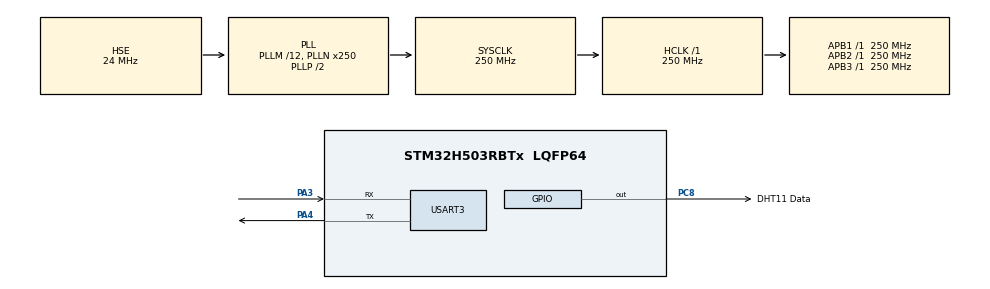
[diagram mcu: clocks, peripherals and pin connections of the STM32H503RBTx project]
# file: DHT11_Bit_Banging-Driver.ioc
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BOOTPATH.BootPathName=LEGACY
BOOTPATH.UserSelectedBootPath=LEGACY
Mcu.Family=STM32H5
Mcu.Name=STM32H503RBTx
Mcu.Package=LQFP64
NUCLEO-H503RB.LD2=false
NVIC.PriorityGroup=NVIC_PRIORITYGROUP_4
PA13(JTMS/SWDIO).GPIO_Label=T_SWDIO
PA13(JTMS/SWDIO).Signal=DEBUG_JTMS-SWDIO
PA14(JTCK/SWCLK).GPIO_Label=T_SWCLK
PA14(JTCK/SWCLK).Signal=DEBUG_JTCK-SWCLK
PA15(JTDI).GPIO_Label=T_JTDI
PA15(JTDI).Signal=DEBUG_JTDI
PA2.Signal=USART2_TX
PA3.Mode=Asynchronous
PA3.Signal=USART3_RX
PA4.Mode=Asynchronous
PA4.Signal=USART3_TX
PB14.GPIO_Label=ARD_D1_TX
PB14.Signal=USART1_TX
PB15.GPIO_Label=ARD_D0_RX
PB15.Signal=USART1_RX
PB3(JTDO/TRACESWO).GPIO_Label=T_SWO
PB3(JTDO/TRACESWO).Signal=DEBUG_JTDO-SWO
PC8.GPIO_Label=DHT11 Data
PC8.GPIO_ModeDefaultOutputPP=GPIO_MODE_OUTPUT_OD
PC8.GPIO_PuPd=GPIO_NOPULL
PC8.GPIO_Speed=GPIO_SPEED_FREQ_MEDIUM
PC8.Signal=GPIO_Output
PH0-OSC_IN(PH0).Mode=HSE-External-Oscillator
PH0-OSC_IN(PH0).Signal=RCC_OSC_IN
PH1-OSC_OUT(PH1).Mode=HSE-External-Oscillator
PH1-OSC_OUT(PH1).Signal=RCC_OSC_OUT
ProjectManager.HeapSize=0x200
ProjectManager.StackSize=0x400
ProjectManager.TargetToolchain=CMake
RCC.ADCFreq_Value=250000000
RCC.AHBFreq_Value=250000000
RCC.APB1Freq_Value=250000000
RCC.APB1TimFreq_Value=250000000
RCC.APB2Freq_Value=250000000
RCC.APB2TimFreq_Value=250000000
RCC.APB3Freq_Value=250000000
RCC.CSI_VALUE=4000000
RCC.CortexFreq_Value=250000000
RCC.EPOD_VALUE=24000000
RCC.HCLKFreq_Value=250000000
RCC.HSE_VALUE=24000000
RCC.HSI48_VALUE=48000000
RCC.HSIDiv=RCC_HSI_DIV1
RCC.HSI_VALUE=64000000
RCC.LSE_VALUE=32768
RCC.LSIRC_VALUE=32000
RCC.PLLM=12
RCC.PLLN=250
RCC.PLLSourceVirtual=RCC_PLL1_SOURCE_HSE
RCC.SYSCLKFreq_VALUE=250000000
RCC.SYSCLKSource=RCC_SYSCLKSOURCE_PLLCLK
RCC.USBFreq_Value=48000000
RCC.VCOOutputFreq_Value=500000000
TIM1.Prescaler=249
USART3.VirtualMode-Asynchronous=VM_ASYNC
VP_BOOTPATH_VS_BOOTPATH.Mode=BP_Activate
VP_CORTEX_M33_NS_VS_Hclk.Mode=Hclk_Mode
VP_MEMORYMAP_VS_MEMORYMAP.Mode=CurAppReg
VP_NUCLEO-H503RB_VS_BSP_COMMON.Mode=COMMON
VP_PWR_VS_LPOM.Mode=PowerOptimisation
VP_PWR_VS_SECSignals.Mode=Security/Privilege
VP_TIM1_VS_ClockSourceINT.Mode=Internal
board=NUCLEO-H503RB

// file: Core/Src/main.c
/* USER CODE BEGIN Header */
/**
 ******************************************************************************
 * @file           : main.c
 * @brief          : Main program body
 ******************************************************************************
 * @attention
 *
 * Copyright (c) 2026 STMicroelectronics.
 * All rights reserved.
 *
 * This software is licensed under terms that can be found in the LICENSE file
 * in the root directory of this software component.
 * If no LICENSE file comes with this software, it is provided AS-IS.
 *
 ******************************************************************************
 */
/* USER CODE END Header */
#include "main.h"

/* USER CODE BEGIN Includes */
#include <stdio.h>
#include <string.h>
#include "DHT11_Driver.h"
/* USER CODE END Includes */

TIM_HandleTypeDef htim1;

UART_HandleTypeDef huart3;

/* USER CODE BEGIN PV */
uint8_t tx_buffer[27] = "Test Recieved !\n\r";
/* USER CODE END PV */

void SystemClock_Config(void);
static void MX_GPIO_Init(void);
static void MX_TIM1_Init(void);
static void MX_USART3_UART_Init(void);

int main(void)
{

  /* MCU Configuration--------------------------------------------------------*/

  /* Reset of all peripherals, Initializes the Flash interface and the Systick. */
  HAL_Init();

  /* Configure the system clock */
  SystemClock_Config();

  /* Initialize all configured peripherals */
  MX_GPIO_Init();
  MX_TIM1_Init();
  MX_USART3_UART_Init();
  /* USER CODE BEGIN 2 */
	HAL_TIM_Base_Start(&htim1);
  /* USER CODE END 2 */

  /* Infinite loop */
  /* USER CODE BEGIN WHILE */
	// see https://www.mouser.com/datasheet/2/758/DHT11-Technical-Data-Sheet-Translated-Version-1143054.pdf?srsltid=AfmBOorSyVOD996zWNFTVFMWIrC0eVVUjCtXqNslasQQP2nxrXqggH95
	while (1) {
		int temp = 0;
		int hum = 0;
		char msg[50];

		// ------ UART Logging ------

		// Call Driver DHT11

		if (DHT11_Read_Data(DHT11_Data_GPIO_Port, DHT11_Data_Pin, &temp, &hum) == 0) {
			// If Success (Return 0)
			sprintf(msg, "Temp: %i C, Hum: %i  %%\r\n", temp, hum);
		} else {
			// If Error (Return -1)
			sprintf(msg, "Error: Sensor Timeout or Checksum Failed\r\n");
		}

		HAL_UART_Transmit(&huart3, (uint8_t*) msg, strlen(msg), HAL_MAX_DELAY);

		// we delay to not overload the sensor
		HAL_Delay(1000);

    /* USER CODE END WHILE */

	}
}

void SystemClock_Config(void)
{
  RCC_OscInitTypeDef RCC_OscInitStruct = {0};
  RCC_ClkInitTypeDef RCC_ClkInitStruct = {0};

  /** Configure the main internal regulator output voltage
  */
  __HAL_PWR_VOLTAGESCALING_CONFIG(PWR_REGULATOR_VOLTAGE_SCALE0);

  while(!__HAL_PWR_GET_FLAG(PWR_FLAG_VOSRDY)) {}

  /** Initializes the RCC Oscillators according to the specified parameters
  * in the RCC_OscInitTypeDef structure.
  */
  RCC_OscInitStruct.OscillatorType = RCC_OSCILLATORTYPE_HSE;
  RCC_OscInitStruct.HSEState = RCC_HSE_ON;
  RCC_OscInitStruct.PLL.PLLState = RCC_PLL_ON;
  RCC_OscInitStruct.PLL.PLLSource = RCC_PLL1_SOURCE_HSE;
  RCC_OscInitStruct.PLL.PLLM = 12;
  RCC_OscInitStruct.PLL.PLLN = 250;
  RCC_OscInitStruct.PLL.PLLP = 2;
  RCC_OscInitStruct.PLL.PLLQ = 2;
  RCC_OscInitStruct.PLL.PLLR = 2;
  RCC_OscInitStruct.PLL.PLLRGE = RCC_PLL1_VCIRANGE_1;
  RCC_OscInitStruct.PLL.PLLVCOSEL = RCC_PLL1_VCORANGE_WIDE;
  RCC_OscInitStruct.PLL.PLLFRACN = 0;
  if (HAL_RCC_OscConfig(&RCC_OscInitStruct) != HAL_OK)
  {
    Error_Handler();
  }

  /** Initializes the CPU, AHB and APB buses clocks
  */
  RCC_ClkInitStruct.ClockType = RCC_CLOCKTYPE_HCLK|RCC_CLOCKTYPE_SYSCLK
                              |RCC_CLOCKTYPE_PCLK1|RCC_CLOCKTYPE_PCLK2
                              |RCC_CLOCKTYPE_PCLK3;
  RCC_ClkInitStruct.SYSCLKSource = RCC_SYSCLKSOURCE_PLLCLK;
  RCC_ClkInitStruct.AHBCLKDivider = RCC_SYSCLK_DIV1;
  RCC_ClkInitStruct.APB1CLKDivider = RCC_HCLK_DIV1;
  RCC_ClkInitStruct.APB2CLKDivider = RCC_HCLK_DIV1;
  RCC_ClkInitStruct.APB3CLKDivider = RCC_HCLK_DIV1;

  if (HAL_RCC_ClockConfig(&RCC_ClkInitStruct, FLASH_LATENCY_5) != HAL_OK)
  {
    Error_Handler();
  }

  /** Configure the programming delay
  */
  __HAL_FLASH_SET_PROGRAM_DELAY(FLASH_PROGRAMMING_DELAY_2);
}

static void MX_TIM1_Init(void)
{

  TIM_ClockConfigTypeDef sClockSourceConfig = {0};
  TIM_MasterConfigTypeDef sMasterConfig = {0};

  htim1.Instance = TIM1;
  htim1.Init.Prescaler = 249;
  htim1.Init.CounterMode = TIM_COUNTERMODE_UP;
  htim1.Init.Period = 65535;
  htim1.Init.ClockDivision = TIM_CLOCKDIVISION_DIV1;
  htim1.Init.RepetitionCounter = 0;
  htim1.Init.AutoReloadPreload = TIM_AUTORELOAD_PRELOAD_DISABLE;
  if (HAL_TIM_Base_Init(&htim1) != HAL_OK)
  {
    Error_Handler();
  }
  sClockSourceConfig.ClockSource = TIM_CLOCKSOURCE_INTERNAL;
  if (HAL_TIM_ConfigClockSource(&htim1, &sClockSourceConfig) != HAL_OK)
  {
    Error_Handler();
  }
  sMasterConfig.MasterOutputTrigger = TIM_TRGO_RESET;
  sMasterConfig.MasterOutputTrigger2 = TIM_TRGO2_RESET;
  sMasterConfig.MasterSlaveMode = TIM_MASTERSLAVEMODE_DISABLE;
  if (HAL_TIMEx_MasterConfigSynchronization(&htim1, &sMasterConfig) != HAL_OK)
  {
    Error_Handler();
  }

}

static void MX_USART3_UART_Init(void)
{

  huart3.Instance = USART3;
  huart3.Init.BaudRate = 115200;
  huart3.Init.WordLength = UART_WORDLENGTH_8B;
  huart3.Init.StopBits = UART_STOPBITS_1;
  huart3.Init.Parity = UART_PARITY_NONE;
  huart3.Init.Mode = UART_MODE_TX_RX;
  huart3.Init.HwFlowCtl = UART_HWCONTROL_NONE;
  huart3.Init.OverSampling = UART_OVERSAMPLING_16;
  huart3.Init.OneBitSampling = UART_ONE_BIT_SAMPLE_DISABLE;
  huart3.Init.ClockPrescaler = UART_PRESCALER_DIV1;
  huart3.AdvancedInit.AdvFeatureInit = UART_ADVFEATURE_NO_INIT;
  if (HAL_UART_Init(&huart3) != HAL_OK)
  {
    Error_Handler();
  }
  if (HAL_UARTEx_SetTxFifoThreshold(&huart3, UART_TXFIFO_THRESHOLD_1_8) != HAL_OK)
  {
    Error_Handler();
  }
  if (HAL_UARTEx_SetRxFifoThreshold(&huart3, UART_RXFIFO_THRESHOLD_1_8) != HAL_OK)
  {
    Error_Handler();
  }
  if (HAL_UARTEx_DisableFifoMode(&huart3) != HAL_OK)
  {
    Error_Handler();
  }

}

static void MX_GPIO_Init(void)
{
  GPIO_InitTypeDef GPIO_InitStruct = {0};

  /* GPIO Ports Clock Enable */
  __HAL_RCC_GPIOH_CLK_ENABLE();
  __HAL_RCC_GPIOA_CLK_ENABLE();
  __HAL_RCC_GPIOB_CLK_ENABLE();
  __HAL_RCC_GPIOC_CLK_ENABLE();

  /*Configure GPIO pin Output Level */
  HAL_GPIO_WritePin(DHT11_Data_GPIO_Port, DHT11_Data_Pin, GPIO_PIN_RESET);

  /*Configure GPIO pin : PA2 */
  GPIO_InitStruct.Pin = GPIO_PIN_2;
  GPIO_InitStruct.Mode = GPIO_MODE_AF_PP;
  GPIO_InitStruct.Pull = GPIO_NOPULL;
  GPIO_InitStruct.Speed = GPIO_SPEED_FREQ_LOW;
  GPIO_InitStruct.Alternate = GPIO_AF7_USART2;
  HAL_GPIO_Init(GPIOA, &GPIO_InitStruct);

  /*Configure GPIO pins : ARD_D1_TX_Pin ARD_D0_RX_Pin */
  GPIO_InitStruct.Pin = ARD_D1_TX_Pin|ARD_D0_RX_Pin;
  GPIO_InitStruct.Mode = GPIO_MODE_AF_PP;
  GPIO_InitStruct.Pull = GPIO_NOPULL;
  GPIO_InitStruct.Speed = GPIO_SPEED_FREQ_LOW;
  GPIO_InitStruct.Alternate = GPIO_AF4_USART1;
  HAL_GPIO_Init(GPIOB, &GPIO_InitStruct);

  /*Configure GPIO pin : DHT11_Data_Pin */
  GPIO_InitStruct.Pin = DHT11_Data_Pin;
  GPIO_InitStruct.Mode = GPIO_MODE_OUTPUT_OD;
  GPIO_InitStruct.Pull = GPIO_NOPULL;
  GPIO_InitStruct.Speed = GPIO_SPEED_FREQ_MEDIUM;
  HAL_GPIO_Init(DHT11_Data_GPIO_Port, &GPIO_InitStruct);

}

void Error_Handler(void)
{
	__disable_irq();
	while (1) {
	}
}
